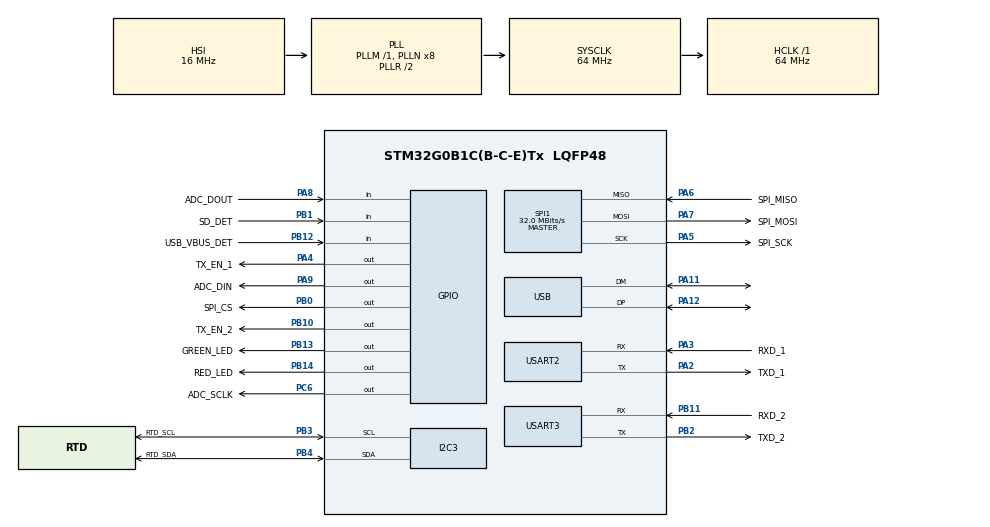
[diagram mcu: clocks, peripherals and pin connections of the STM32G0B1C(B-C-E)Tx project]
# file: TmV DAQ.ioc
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Dma.Request0=USART2_RX
Dma.Request1=USART2_TX
Dma.Request2=USART3_RX
Dma.Request3=USART3_TX
Dma.USART2_RX.0.Direction=DMA_PERIPH_TO_MEMORY
Dma.USART2_RX.0.EventEnable=DISABLE
Dma.USART2_RX.0.Instance=DMA1_Channel1
Dma.USART2_RX.0.MemDataAlignment=DMA_MDATAALIGN_BYTE
Dma.USART2_RX.0.MemInc=DMA_MINC_ENABLE
Dma.USART2_RX.0.Mode=DMA_CIRCULAR
Dma.USART2_RX.0.PeriphDataAlignment=DMA_PDATAALIGN_BYTE
Dma.USART2_RX.0.PeriphInc=DMA_PINC_DISABLE
Dma.USART2_RX.0.Polarity=HAL_DMAMUX_REQ_GEN_RISING
Dma.USART2_RX.0.Priority=DMA_PRIORITY_MEDIUM
Dma.USART2_RX.0.RequestNumber=1
Dma.USART2_RX.0.SignalID=NONE
Dma.USART2_RX.0.SyncEnable=DISABLE
Dma.USART2_RX.0.SyncPolarity=HAL_DMAMUX_SYNC_NO_EVENT
Dma.USART2_RX.0.SyncRequestNumber=1
Dma.USART2_RX.0.SyncSignalID=NONE
Dma.USART2_TX.1.Direction=DMA_MEMORY_TO_PERIPH
Dma.USART2_TX.1.EventEnable=DISABLE
Dma.USART2_TX.1.Instance=DMA1_Channel2
Dma.USART2_TX.1.MemDataAlignment=DMA_MDATAALIGN_BYTE
Dma.USART2_TX.1.MemInc=DMA_MINC_ENABLE
Dma.USART2_TX.1.Mode=DMA_NORMAL
Dma.USART2_TX.1.PeriphDataAlignment=DMA_PDATAALIGN_BYTE
Dma.USART2_TX.1.PeriphInc=DMA_PINC_DISABLE
Dma.USART2_TX.1.Polarity=HAL_DMAMUX_REQ_GEN_RISING
Dma.USART2_TX.1.Priority=DMA_PRIORITY_LOW
Dma.USART2_TX.1.RequestNumber=1
Dma.USART2_TX.1.SignalID=NONE
Dma.USART2_TX.1.SyncEnable=DISABLE
Dma.USART2_TX.1.SyncPolarity=HAL_DMAMUX_SYNC_NO_EVENT
Dma.USART2_TX.1.SyncRequestNumber=1
Dma.USART2_TX.1.SyncSignalID=NONE
Dma.USART3_RX.2.Direction=DMA_PERIPH_TO_MEMORY
Dma.USART3_RX.2.EventEnable=DISABLE
Dma.USART3_RX.2.Instance=DMA1_Channel3
Dma.USART3_RX.2.MemDataAlignment=DMA_MDATAALIGN_BYTE
Dma.USART3_RX.2.MemInc=DMA_MINC_ENABLE
Dma.USART3_RX.2.Mode=DMA_CIRCULAR
Dma.USART3_RX.2.PeriphDataAlignment=DMA_PDATAALIGN_BYTE
Dma.USART3_RX.2.PeriphInc=DMA_PINC_DISABLE
Dma.USART3_RX.2.Polarity=HAL_DMAMUX_REQ_GEN_RISING
Dma.USART3_RX.2.Priority=DMA_PRIORITY_MEDIUM
Dma.USART3_RX.2.RequestNumber=1
Dma.USART3_RX.2.SignalID=NONE
Dma.USART3_RX.2.SyncEnable=DISABLE
Dma.USART3_RX.2.SyncPolarity=HAL_DMAMUX_SYNC_NO_EVENT
Dma.USART3_RX.2.SyncRequestNumber=1
Dma.USART3_RX.2.SyncSignalID=NONE
Dma.USART3_TX.3.Direction=DMA_MEMORY_TO_PERIPH
Dma.USART3_TX.3.EventEnable=DISABLE
Dma.USART3_TX.3.Instance=DMA1_Channel4
Dma.USART3_TX.3.MemDataAlignment=DMA_MDATAALIGN_BYTE
Dma.USART3_TX.3.MemInc=DMA_MINC_ENABLE
Dma.USART3_TX.3.Mode=DMA_NORMAL
Dma.USART3_TX.3.PeriphDataAlignment=DMA_PDATAALIGN_BYTE
Dma.USART3_TX.3.PeriphInc=DMA_PINC_DISABLE
Dma.USART3_TX.3.Polarity=HAL_DMAMUX_REQ_GEN_RISING
Dma.USART3_TX.3.Priority=DMA_PRIORITY_LOW
Dma.USART3_TX.3.RequestNumber=1
Dma.USART3_TX.3.SignalID=NONE
Dma.USART3_TX.3.SyncEnable=DISABLE
Dma.USART3_TX.3.SyncPolarity=HAL_DMAMUX_SYNC_NO_EVENT
Dma.USART3_TX.3.SyncRequestNumber=1
Dma.USART3_TX.3.SyncSignalID=NONE
FREERTOS.INCLUDE_xEventGroupSetBitFromISR=0
FREERTOS.INCLUDE_xTimerPendFunctionCall=0
FREERTOS.Tasks01=defaultTask,0,64,StartDefaultTask,Default,NULL,Dynamic,NULL,NULL
FREERTOS.configMINIMAL_STACK_SIZE=64
FREERTOS.configTOTAL_HEAP_SIZE=10240
FREERTOS.configUSE_TIMERS=0
I2C3.Timing=0x10B17DB5
Mcu.Family=STM32G0
Mcu.Name=STM32G0B1C(B-C-E)Tx
Mcu.Package=LQFP48
NVIC.DMA1_Ch4_7_DMA2_Ch1_5_DMAMUX1_OVR_IRQn=true\:3\:0\:false\:false\:true\:true\:false\:true\:true
NVIC.DMA1_Channel1_IRQn=true\:3\:0\:false\:false\:true\:true\:false\:true\:true
NVIC.DMA1_Channel2_3_IRQn=true\:3\:0\:false\:false\:true\:true\:false\:true\:true
NVIC.FLASH_IRQn=true\:3\:0\:false\:true\:true\:1\:true\:true\:true\:true
NVIC.TIM6_DAC_LPTIM1_IRQn=true\:3\:0\:false\:false\:true\:false\:false\:true\:true
NVIC.TimeBase=TIM6_DAC_LPTIM1_IRQn
NVIC.TimeBaseIP=TIM6
NVIC.USART2_LPUART2_IRQn=true\:3\:0\:false\:false\:true\:true\:true\:true\:true
NVIC.USART3_4_5_6_LPUART1_IRQn=true\:3\:0\:false\:false\:true\:true\:true\:true\:true
PA11\ [PA9].Mode=Device
PA11\ [PA9].Signal=USB_DM
PA12\ [PA10].Mode=Device
PA12\ [PA10].Signal=USB_DP
PA13.Mode=Serial_Wire
PA13.Signal=SYS_SWDIO
PA14-BOOT0.Mode=Serial_Wire
PA14-BOOT0.Signal=SYS_SWCLK
PA2.GPIO_Label=TXD_1
PA2.Mode=Asynchronous
PA2.Signal=USART2_TX
PA3.GPIO_Label=RXD_1
PA3.Mode=Asynchronous
PA3.Signal=USART2_RX
PA4.GPIO_Label=TX_EN_1
PA4.Signal=GPIO_Output
PA5.GPIO_Label=SPI_SCK
PA5.GPIO_PuPd=GPIO_NOPULL
PA5.GPIO_Speed=GPIO_SPEED_FREQ_VERY_HIGH
PA5.Mode=Full_Duplex_Master
PA5.Signal=SPI1_SCK
PA6.GPIO_Label=SPI_MISO
PA6.GPIO_PuPd=GPIO_NOPULL
PA6.GPIO_Speed=GPIO_SPEED_FREQ_VERY_HIGH
PA6.Mode=Full_Duplex_Master
PA6.Signal=SPI1_MISO
PA7.GPIO_Label=SPI_MOSI
PA7.GPIO_PuPd=GPIO_NOPULL
PA7.GPIO_Speed=GPIO_SPEED_FREQ_VERY_HIGH
PA7.Mode=Full_Duplex_Master
PA7.Signal=SPI1_MOSI
PA8.GPIO_Label=ADC_DOUT
PA8.Signal=GPIO_Input
PA9.GPIO_Label=ADC_DIN
PA9.GPIO_Speed=GPIO_SPEED_FREQ_VERY_HIGH
PA9.Signal=GPIO_Output
PB0.GPIO_Label=SPI_CS
PB0.GPIO_PuPd=GPIO_PULLUP
PB0.GPIO_Speed=GPIO_SPEED_FREQ_VERY_HIGH
PB0.Signal=GPIO_Output
PB1.GPIO_Label=SD_DET
PB1.Signal=GPIO_Input
PB10.GPIO_Label=TX_EN_2
PB10.Signal=GPIO_Output
PB11.GPIO_Label=RXD_2
PB11.Mode=Asynchronous
PB11.Signal=USART3_RX
PB12.GPIO_Label=USB_VBUS_DET
PB12.Signal=GPIO_Input
PB13.GPIO_Label=GREEN_LED
PB13.Signal=GPIO_Output
PB14.GPIO_Label=RED_LED
PB14.Signal=GPIO_Output
PB2.GPIO_Label=TXD_2
PB2.Mode=Asynchronous
PB2.Signal=USART3_TX
PB3.GPIO_Label=RTD_SCL
PB3.Mode=I2C
PB3.Signal=I2C3_SCL
PB4.GPIO_Label=RTD_SDA
PB4.Mode=I2C
PB4.Signal=I2C3_SDA
PC14-OSC32_IN\ (PC14).Mode=LSE-External-Oscillator
PC14-OSC32_IN\ (PC14).Signal=RCC_OSC32_IN
PC15-OSC32_OUT\ (PC15).Mode=LSE-External-Oscillator
PC15-OSC32_OUT\ (PC15).Signal=RCC_OSC32_OUT
PC6.GPIO_Label=ADC_SCLK
PC6.GPIO_Speed=GPIO_SPEED_FREQ_VERY_HIGH
PC6.Signal=GPIO_Output
PF0-OSC_IN\ (PF0).Mode=HSE-External-Oscillator
PF0-OSC_IN\ (PF0).Signal=RCC_OSC_IN
PF1-OSC_OUT\ (PF1).Mode=HSE-External-Oscillator
PF1-OSC_OUT\ (PF1).Signal=RCC_OSC_OUT
ProjectManager.HeapSize=0x1000
ProjectManager.StackSize=0x400
ProjectManager.TargetToolchain=MDK-ARM V5.32
RCC.ADCFreq_Value=64000000
RCC.AHBFreq_Value=64000000
RCC.CortexFreq_Value=64000000
RCC.EXTERNAL_CLOCK_VALUE=48000
RCC.HCLKFreq_Value=64000000
RCC.HSE_VALUE=8000000
RCC.HSI48_VALUE=48000000
RCC.HSI_VALUE=16000000
RCC.SYSCLKFreq_VALUE=64000000
RCC.SYSCLKSource=RCC_SYSCLKSOURCE_PLLCLK
RCC.USBFreq_Value=48000000
RCC.VCOOutputFreq_Value=128000000
SPI1.CalculateBaudRate=32.0 MBits/s
SPI1.Direction=SPI_DIRECTION_2LINES
SPI1.Mode=SPI_MODE_MASTER
SPI1.VirtualType=VM_MASTER
USART2.VirtualMode-Asynchronous=VM_ASYNC
USART3.VirtualMode-Asynchronous=VM_ASYNC
USB_DEVICE.CLASS_NAME_FS=MSC
USB_DEVICE.VirtualMode=Msc
USB_DEVICE.VirtualModeFS=Msc_FS
VP_FATFS_VS_Generic.Mode=User_defined
VP_FREERTOS_VS_CMSIS_V1.Mode=CMSIS_V1
VP_RTC_VS_RTC_Activate.Mode=RTC_Enabled
VP_SYS_VS_DBSignals.Mode=DisableDeadBatterySignals
VP_SYS_VS_tim6.Mode=TIM6
VP_USB_DEVICE_VS_USB_DEVICE_MSC_FS.Mode=MSC_FS
board=custom

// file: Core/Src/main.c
/* USER CODE BEGIN Header */
/**
 ******************************************************************************
 * @file           : main.c
 * @brief          : Main program body
 ******************************************************************************
 * @attention
 *
 * Copyright (c) 2025 STMicroelectronics.
 * All rights reserved.
 *
 * This software is licensed under terms that can be found in the LICENSE file
 * in the root directory of this software component.
 * If no LICENSE file comes with this software, it is provided AS-IS.
 *
 ******************************************************************************
 */
/* USER CODE END Header */
#include "main.h"
#include "cmsis_os.h"
#include "dma.h"
#include "app_fatfs.h"
#include "i2c.h"
#include "rtc.h"
#include "spi.h"
#include "usart.h"
#include "usb_device.h"
#include "gpio.h"

/* USER CODE BEGIN Includes */
#include "dma_uart.h"
#include "eeprom_emul.h"
#include "freeRTOS.h"
#include "measure_millivolt.h"
#include "task.h"

/* USER CODE END Includes */

void SystemClock_Config(void);
void MX_FREERTOS_Init(void);
static void MX_NVIC_Init(void);

int main(void)
{

  /* MCU Configuration--------------------------------------------------------*/

  /* Reset of all peripherals, Initializes the Flash interface and the Systick. */
  HAL_Init();

  /* Configure the system clock */
  SystemClock_Config();

  /* Initialize all configured peripherals */
  MX_GPIO_Init();
  MX_DMA_Init();
  MX_USART2_UART_Init();
  MX_SPI1_Init();
  if (MX_FATFS_Init() != APP_OK) {
    Error_Handler();
  }
  MX_I2C3_Init();
  MX_USART3_UART_Init();
  MX_RTC_Init();

  /* Initialize interrupts */
  MX_NVIC_Init();
  /* USER CODE BEGIN 2 */
    /* Unlock the Flash Program Erase controller */
    HAL_FLASH_Unlock();
    /* Activate NMI generation when two errors are detected */
    __HAL_FLASH_ENABLE_IT(FLASH_IT_ECCC);
    EE_Status status = EE_Init(EE_FORCED_ERASE);
    if (status != EE_OK)
    {
        Error_Handler();
    }

    start_rs485_demo_task();
    start_measure_millivolt_task();
    start_rs485_1_printf_task();
  /* USER CODE END 2 */

  /* Call init function for freertos objects (in cmsis_os2.c) */
  MX_FREERTOS_Init();

  /* Start scheduler */
  osKernelStart();

  /* We should never get here as control is now taken by the scheduler */

  /* Infinite loop */
    while (1)
    {

    }
}

void SystemClock_Config(void)
{
  RCC_OscInitTypeDef RCC_OscInitStruct = {0};
  RCC_ClkInitTypeDef RCC_ClkInitStruct = {0};

  /** Configure the main internal regulator output voltage
  */
  HAL_PWREx_ControlVoltageScaling(PWR_REGULATOR_VOLTAGE_SCALE1);

  /** Initializes the RCC Oscillators according to the specified parameters
  * in the RCC_OscInitTypeDef structure.
  */
  RCC_OscInitStruct.OscillatorType = RCC_OSCILLATORTYPE_HSI|RCC_OSCILLATORTYPE_LSI
                              |RCC_OSCILLATORTYPE_HSI48;
  RCC_OscInitStruct.HSIState = RCC_HSI_ON;
  RCC_OscInitStruct.HSI48State = RCC_HSI48_ON;
  RCC_OscInitStruct.HSIDiv = RCC_HSI_DIV1;
  RCC_OscInitStruct.HSICalibrationValue = RCC_HSICALIBRATION_DEFAULT;
  RCC_OscInitStruct.LSIState = RCC_LSI_ON;
  RCC_OscInitStruct.PLL.PLLState = RCC_PLL_ON;
  RCC_OscInitStruct.PLL.PLLSource = RCC_PLLSOURCE_HSI;
  RCC_OscInitStruct.PLL.PLLM = RCC_PLLM_DIV1;
  RCC_OscInitStruct.PLL.PLLN = 8;
  RCC_OscInitStruct.PLL.PLLP = RCC_PLLP_DIV2;
  RCC_OscInitStruct.PLL.PLLQ = RCC_PLLQ_DIV2;
  RCC_OscInitStruct.PLL.PLLR = RCC_PLLR_DIV2;
  if (HAL_RCC_OscConfig(&RCC_OscInitStruct) != HAL_OK)
  {
    Error_Handler();
  }

  /** Initializes the CPU, AHB and APB buses clocks
  */
  RCC_ClkInitStruct.ClockType = RCC_CLOCKTYPE_HCLK|RCC_CLOCKTYPE_SYSCLK
                              |RCC_CLOCKTYPE_PCLK1;
  RCC_ClkInitStruct.SYSCLKSource = RCC_SYSCLKSOURCE_PLLCLK;
  RCC_ClkInitStruct.AHBCLKDivider = RCC_SYSCLK_DIV1;
  RCC_ClkInitStruct.APB1CLKDivider = RCC_HCLK_DIV1;

  if (HAL_RCC_ClockConfig(&RCC_ClkInitStruct, FLASH_LATENCY_2) != HAL_OK)
  {
    Error_Handler();
  }
}

/**
  * @brief NVIC Configuration.
  * @retval None
  */
static void MX_NVIC_Init(void)
{
  /* FLASH_IRQn interrupt configuration */
  HAL_NVIC_SetPriority(FLASH_IRQn, 3, 0);
  HAL_NVIC_EnableIRQ(FLASH_IRQn);
}

void HAL_TIM_PeriodElapsedCallback(TIM_HandleTypeDef *htim)
{
  if (htim->Instance == TIM6) {
    HAL_IncTick();
  }
}

void Error_Handler(void)
{
    __disable_irq();
    while (1)
    {
    }
}

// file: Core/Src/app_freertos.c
/* USER CODE BEGIN Header */
/**
  ******************************************************************************
  * File Name          : app_freertos.c
  * Description        : Code for freertos applications
  ******************************************************************************
  * @attention
  *
  * Copyright (c) 2025 STMicroelectronics.
  * All rights reserved.
  *
  * This software is licensed under terms that can be found in the LICENSE file
  * in the root directory of this software component.
  * If no LICENSE file comes with this software, it is provided AS-IS.
  *
  ******************************************************************************
  */
/* USER CODE END Header */

#include "FreeRTOS.h"
#include "task.h"
#include "main.h"
#include "cmsis_os.h"

/* USER CODE BEGIN Includes */
#include "usb_device.h"
/* USER CODE END Includes */

osThreadId defaultTaskHandle;

void StartDefaultTask(void const * argument);

void MX_FREERTOS_Init(void); /* (MISRA C 2004 rule 8.1) */

void MX_FREERTOS_Init(void) {

  /* Create the thread(s) */
  /* definition and creation of defaultTask */
  osThreadDef(defaultTask, StartDefaultTask, osPriorityNormal, 0, 64);
  defaultTaskHandle = osThreadCreate(osThread(defaultTask), NULL);

}

void StartDefaultTask(void const * argument)
{
  /* init code for USB_Device */
  MX_USB_Device_Init();
  for(;;)
  {
    osDelay(1);
  }
}
